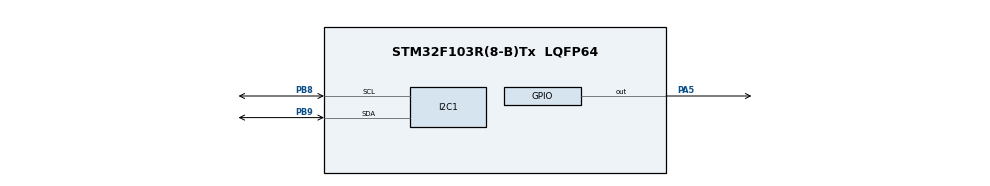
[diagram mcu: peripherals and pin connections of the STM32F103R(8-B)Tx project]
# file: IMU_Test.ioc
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Mcu.Family=STM32F1
Mcu.Name=STM32F103R(8-B)Tx
Mcu.Package=LQFP64
NVIC.PriorityGroup=NVIC_PRIORITYGROUP_4
PA5.Signal=GPIO_Output
PB8.Mode=I2C
PB8.Signal=I2C1_SCL
PB9.Mode=I2C
PB9.Signal=I2C1_SDA
ProjectManager.HeapSize=0x200
ProjectManager.StackSize=0x400
ProjectManager.TargetToolchain=MDK-ARM V5
RCC.APB1Freq_Value=8000000
RCC.APB2Freq_Value=8000000
VP_SYS_VS_ND.Mode=No_Debug
board=custom

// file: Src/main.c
/* USER CODE BEGIN Header */
/**
  ******************************************************************************
  * @file           : main.c
  * @brief          : Main program body
  ******************************************************************************
  ** This notice applies to any and all portions of this file
  * that are not between comment pairs USER CODE BEGIN and
  * USER CODE END. Other portions of this file, whether
  * inserted by the user or by software development tools
  * are owned by their respective copyright owners.
  *
  * COPYRIGHT(c) 2019 STMicroelectronics
  *
  * Redistribution and use in source and binary forms, with or without modification,
  * are permitted provided that the following conditions are met:
  *   1. Redistributions of source code must retain the above copyright notice,
  *      this list of conditions and the following disclaimer.
  *   2. Redistributions in binary form must reproduce the above copyright notice,
  *      this list of conditions and the following disclaimer in the documentation
  *      and/or other materials provided with the distribution.
  *   3. Neither the name of STMicroelectronics nor the names of its contributors
  *      may be used to endorse or promote products derived from this software
  *      without specific prior written permission.
  *
  * THIS SOFTWARE IS PROVIDED BY THE COPYRIGHT HOLDERS AND CONTRIBUTORS "AS IS"
  * AND ANY EXPRESS OR IMPLIED WARRANTIES, INCLUDING, BUT NOT LIMITED TO, THE
  * IMPLIED WARRANTIES OF MERCHANTABILITY AND FITNESS FOR A PARTICULAR PURPOSE ARE
  * DISCLAIMED. IN NO EVENT SHALL THE COPYRIGHT HOLDER OR CONTRIBUTORS BE LIABLE
  * FOR ANY DIRECT, INDIRECT, INCIDENTAL, SPECIAL, EXEMPLARY, OR CONSEQUENTIAL
  * DAMAGES (INCLUDING, BUT NOT LIMITED TO, PROCUREMENT OF SUBSTITUTE GOODS OR
  * SERVICES; LOSS OF USE, DATA, OR PROFITS; OR BUSINESS INTERRUPTION) HOWEVER
  * CAUSED AND ON ANY THEORY OF LIABILITY, WHETHER IN CONTRACT, STRICT LIABILITY,
  * OR TORT (INCLUDING NEGLIGENCE OR OTHERWISE) ARISING IN ANY WAY OUT OF THE USE
  * OF THIS SOFTWARE, EVEN IF ADVISED OF THE POSSIBILITY OF SUCH DAMAGE.
  *
  ******************************************************************************
  */
/* USER CODE END Header */

#include "main.h"
#include "BNO055_IMU.h"

I2C_HandleTypeDef hi2c1;

/* USER CODE BEGIN PV */
	// variables to store the offsets
uint8_t gyro_offset[RCV_DATA_LEN] = {0};
uint8_t magnet_offset[RCV_DATA_LEN] = {0};
/* USER CODE END PV */

void SystemClock_Config(void);
static void MX_GPIO_Init(void);
static void MX_I2C1_Init(void);

/* USER CODE BEGIN 0 */
uint8_t rxData;
/* USER CODE END 0 */

int main(void)
{

  /* MCU Configuration--------------------------------------------------------*/

  /* Reset of all peripherals, Initializes the Flash interface and the Systick. */
  HAL_Init();

  /* Configure the system clock */
  SystemClock_Config();

  /* Initialize all configured peripherals */
  MX_GPIO_Init();
  MX_I2C1_Init();
  /* USER CODE BEGIN 2 */

	// initialize and calibrate
	IMU_init(&hi2c1, OPERATION_MODE_MAGGYRO);
	HAL_Delay(10);

	// switch to config to save offsets
	set_mode(&hi2c1, OPERATION_MODE_CONFIG);
	HAL_Delay(10);
	get_mag_offsets(&hi2c1, magnet_offset);
	get_gyr_offsets(&hi2c1, gyro_offset);

	// switch back to sensor mode
	set_mode(&hi2c1, OPERATION_MODE_MAGGYRO);

	float mag_vector[3] = {0};
	float gyr_vector[3] = {0};
	float acc_vector[3] = {0};

  /* USER CODE END 2 */

  /* Infinite loop */
  /* USER CODE BEGIN WHILE */
  while (1)
  {

		get_mag_data(&hi2c1, mag_vector);
		get_gyr_data(&hi2c1, gyr_vector);
		get_acc_data(&hi2c1, acc_vector);

    /* USER CODE END WHILE */

  }
}

void SystemClock_Config(void)
{
  RCC_OscInitTypeDef RCC_OscInitStruct = {0};
  RCC_ClkInitTypeDef RCC_ClkInitStruct = {0};

  /**Initializes the CPU, AHB and APB busses clocks
  */
  RCC_OscInitStruct.OscillatorType = RCC_OSCILLATORTYPE_HSI;
  RCC_OscInitStruct.HSIState = RCC_HSI_ON;
  RCC_OscInitStruct.HSICalibrationValue = RCC_HSICALIBRATION_DEFAULT;
  RCC_OscInitStruct.PLL.PLLState = RCC_PLL_NONE;
  if (HAL_RCC_OscConfig(&RCC_OscInitStruct) != HAL_OK)
  {
    Error_Handler();
  }
  /**Initializes the CPU, AHB and APB busses clocks
  */
  RCC_ClkInitStruct.ClockType = RCC_CLOCKTYPE_HCLK|RCC_CLOCKTYPE_SYSCLK
                              |RCC_CLOCKTYPE_PCLK1|RCC_CLOCKTYPE_PCLK2;
  RCC_ClkInitStruct.SYSCLKSource = RCC_SYSCLKSOURCE_HSI;
  RCC_ClkInitStruct.AHBCLKDivider = RCC_SYSCLK_DIV1;
  RCC_ClkInitStruct.APB1CLKDivider = RCC_HCLK_DIV1;
  RCC_ClkInitStruct.APB2CLKDivider = RCC_HCLK_DIV1;

  if (HAL_RCC_ClockConfig(&RCC_ClkInitStruct, FLASH_LATENCY_0) != HAL_OK)
  {
    Error_Handler();
  }
}

static void MX_I2C1_Init(void)
{

  hi2c1.Instance = I2C1;
  hi2c1.Init.ClockSpeed = 400000;
  hi2c1.Init.DutyCycle = I2C_DUTYCYCLE_2;
  hi2c1.Init.OwnAddress1 = 0;
  hi2c1.Init.AddressingMode = I2C_ADDRESSINGMODE_7BIT;
  hi2c1.Init.DualAddressMode = I2C_DUALADDRESS_DISABLE;
  hi2c1.Init.OwnAddress2 = 0;
  hi2c1.Init.GeneralCallMode = I2C_GENERALCALL_DISABLE;
  hi2c1.Init.NoStretchMode = I2C_NOSTRETCH_DISABLE;
  if (HAL_I2C_Init(&hi2c1) != HAL_OK)
  {
    Error_Handler();
  }

}

static void MX_GPIO_Init(void)
{
  GPIO_InitTypeDef GPIO_InitStruct = {0};

  /* GPIO Ports Clock Enable */
  __HAL_RCC_GPIOA_CLK_ENABLE();
  __HAL_RCC_GPIOB_CLK_ENABLE();

  /*Configure GPIO pin Output Level */
  HAL_GPIO_WritePin(GPIOA, GPIO_PIN_5, GPIO_PIN_RESET);

  /*Configure GPIO pin : PA5 */
  GPIO_InitStruct.Pin = GPIO_PIN_5;
  GPIO_InitStruct.Mode = GPIO_MODE_OUTPUT_PP;
  GPIO_InitStruct.Pull = GPIO_NOPULL;
  GPIO_InitStruct.Speed = GPIO_SPEED_FREQ_LOW;
  HAL_GPIO_Init(GPIOA, &GPIO_InitStruct);

}

// =================================================================================
/* USER CODE BEGIN 4 */

// =================================================================================
/* USER CODE END 4 */

void Error_Handler(void)
{
}

/************************ (C) COPYRIGHT STMicroelectronics *****END OF FILE****/
